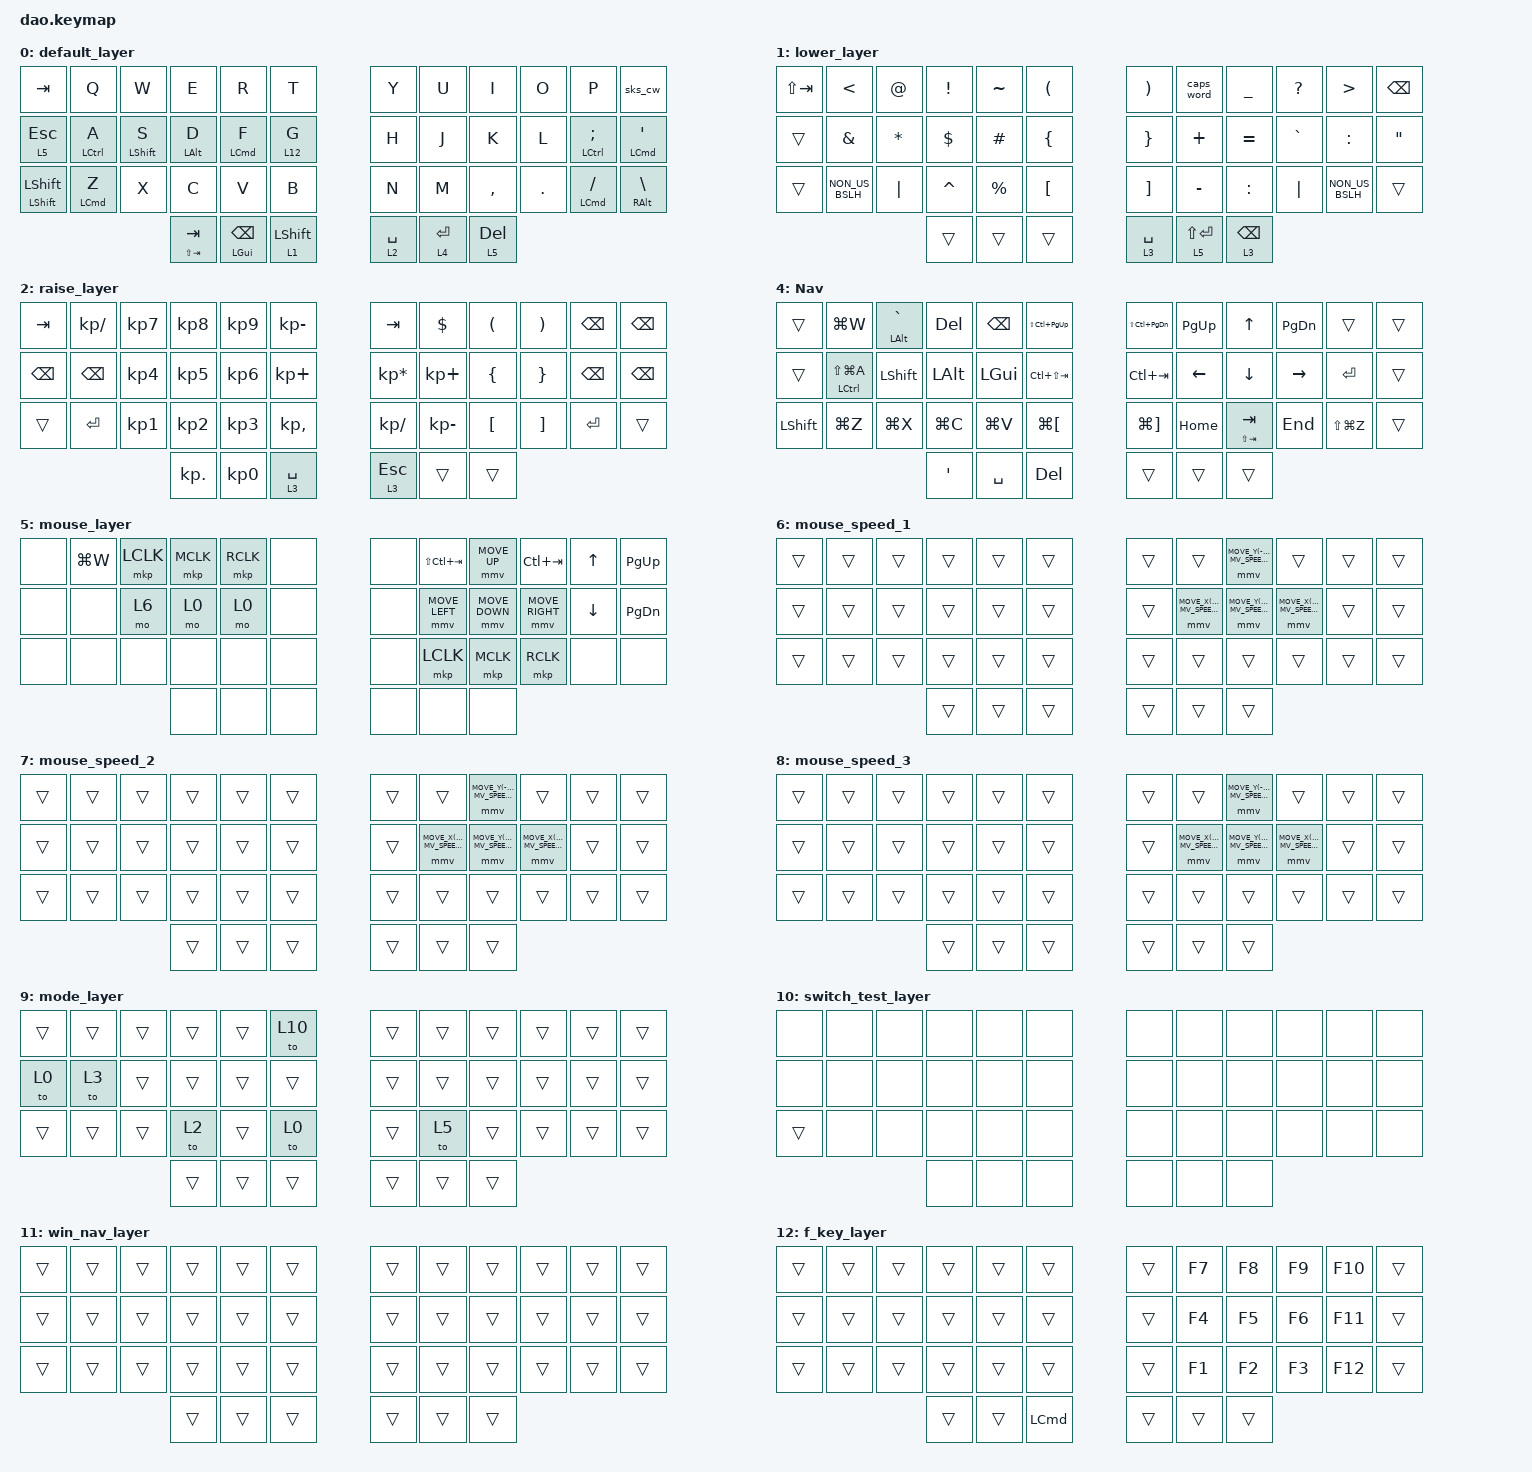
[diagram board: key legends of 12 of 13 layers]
/*
 * Copyright (c) 2021 Rafael Yumagulov
 *
 * SPDX-License-Identifier: MIT
 */

#define MOUSE_MV_SPEED_1 200
#define MOUSE_MV_SPEED_2 400
#define MOUSE_MV_SPEED_3 600

#include <behaviors.dtsi>
#include <dt-bindings/zmk/bt.h>
#include <dt-bindings/zmk/keys.h>
#include <dt-bindings/zmk/mouse.h>
#include <behaviors/mouse_keys.dtsi>

#define DEF 0
#define LWR 1
#define RSE 2
#define ADJ 3

&lt { quick_tap_ms = <200>; };

&mt { quick_tap_ms = <200>; };

&sk { quick-release; };

/*
* &mmv_const {
*     delay-ms = <0>;
*     time-to-max-speed-ms = <0>;
*     acceleration-exponent = <0>;
* };
*/

/ {
    chosen {
        zmk,matrix_transform = &default_transform;

        // zmk,matrix_transform = &extra_keys_transform;
    };
};

/ {
    behaviors {
        sks_cw: sks_cw {
            compatible = "zmk,behavior-tap-dance";
            label = "SKS_CW";
            #binding-cells = <0>;
            bindings = <&sk LSHIFT>, <&caps_word>;
        };

        kp_mod_tap_pref: kp_mod_tap_pref {
            compatible = "zmk,behavior-hold-tap";
            label = "KP_MOD_TAP_PREF";
            bindings = <&kp>, <&kp>;

            #binding-cells = <2>;
            tapping-term-ms = <200>;
            quick-tap-ms = <150>;
            flavor = "tap-preferred";
        };

        sks_mod: sks_mod {
            compatible = "zmk,behavior-hold-tap";
            label = "SKS_MOD";
            bindings = <&kp>, <&sk>;

            #binding-cells = <2>;
            tapping-term-ms = <200>;
            quick-tap-ms = <150>;
            flavor = "balanced";
        };

        krepeat_mod: krepeat_mod {
            compatible = "zmk,behavior-hold-tap";
            label = "KREPEAT_MOD";
            bindings = <&kp>, <&key_repeat>;

            #binding-cells = <2>;
            tapping-term-ms = <200>;
            quick-tap-ms = <150>;
            flavor = "balanced";
        };

        kp_layer_hold_pref: kp_layer_hold_pref {
            compatible = "zmk,behavior-hold-tap";
            label = "KP_LAYER_HOLD_PREF";
            bindings = <&mo>, <&kp>;

            #binding-cells = <2>;
            tapping-term-ms = <200>;
            quick-tap-ms = <150>;
        };

        kp_layer_tap_pref: kp_layer_tap_pref {
            compatible = "zmk,behavior-hold-tap";
            label = "KP_LAYER_TAP_PREF";
            bindings = <&mo>, <&kp>;

            #binding-cells = <2>;
            tapping-term-ms = <200>;
            quick-tap-ms = <150>;
            flavor = "tap-preferred";
        };

        kp_mod_hold_pref: kp_mod_hold_pref {
            compatible = "zmk,behavior-hold-tap";
            label = "KP_MOD_HOLD_PREF";
            bindings = <&kp>, <&kp>;

            #binding-cells = <2>;
            tapping-term-ms = <200>;
            quick-tap-ms = <150>;
            flavor = "hold-preferred";
        };

        sks_layer: sks_layer {
            compatible = "zmk,behavior-hold-tap";
            label = "SKS_LAYER";
            bindings = <&mo>, <&sk>;

            #binding-cells = <2>;
            tapping-term-ms = <200>;
            quick-tap-ms = <150>;
            flavor = "balanced";
        };

        kp_layer_balanced: kp_layer_balanced {
            compatible = "zmk,behavior-hold-tap";
            label = "KP_LAYER_BALANCED";
            bindings = <&mo>, <&kp>;

            #binding-cells = <2>;
            tapping-term-ms = <200>;
            quick-tap-ms = <150>;
            flavor = "balanced";
        };

        sks_layer_hold_pref: sks_layer_hold_pref {
            compatible = "zmk,behavior-hold-tap";
            label = "SKS_LAYER_HOLD_PREF";
            bindings = <&mo>, <&sk>;

            #binding-cells = <2>;
            tapping-term-ms = <200>;
            quick-tap-ms = <150>;
            flavor = "hold-preferred";
        };
    };

    combos {
        compatible = "zmk,combos";

        caps_word {
            bindings = <&caps_word>;
            key-positions = <37 40>;
        };

        mode_layer {
            bindings = <&tog 9>;
            key-positions = <0 38>;
        };
    };

    keymap {
        compatible = "zmk,keymap";

        default_layer {
            bindings = <
&kp TAB                 &kp Q                     &kp W                          &kp E                        &kp R                             &kp T                          &kp Y                        &kp U                         &kp I      &kp O    &kp P                             &sks_cw
&lt 5 ESC               &kp_mod_tap_pref LCTRL A  &kp_mod_tap_pref LEFT_SHIFT S  &kp_mod_tap_pref LEFT_ALT D  &kp_mod_tap_pref LCMD F           &lt 12 G                       &kp H                        &kp J                         &kp K      &kp L    &kp_mod_tap_pref LCTRL SEMICOLON  &kp_mod_tap_pref LCMD SINGLE_QUOTE
&sks_mod LSHIFT LSHIFT  &kp_mod_tap_pref LCMD Z   &kp X                          &kp C                        &kp V                             &kp B                          &kp N                        &kp M                         &kp COMMA  &kp DOT  &kp_mod_tap_pref LCMD SLASH       &mt RALT BSLH
                                                                                 &mt LS(TAB) TAB              &kp_mod_hold_pref LGUI BACKSPACE  &sks_layer_hold_pref 1 LSHIFT  &kp_layer_hold_pref 2 SPACE  &kp_layer_hold_pref 4 RETURN  &lt 5 DEL
            >;
        };

        lower_layer {
            bindings = <
&kp LS(TAB)  &kp LESS_THAN    &kp AT_SIGN  &kp EXCL    &kp TILDE    &kp LEFT_PARENTHESIS  &kp RIGHT_PARENTHESIS  &caps_word                        &kp UNDERSCORE   &kp QUESTION  &kp GREATER_THAN  &kp BACKSPACE
&trans       &kp AMPERSAND    &kp STAR     &kp DOLLAR  &kp HASH     &kp LEFT_BRACE        &kp RIGHT_BRACE        &kp PLUS                          &kp EQUAL        &kp GRAVE     &kp COLON         &kp DOUBLE_QUOTES
&trans       &kp NON_US_BSLH  &kp PIPE     &kp CARET   &kp PERCENT  &kp LEFT_BRACKET      &kp RIGHT_BRACKET      &kp MINUS                         &kp COLON        &kp PIPE      &kp NON_US_BSLH   &trans
                                           &trans      &trans       &trans                &lt 3 SPACE            &kp_layer_hold_pref 5 LS(RETURN)  &lt 3 BACKSPACE
            >;
        };

        raise_layer {
            bindings = <
&kp TAB        &kp KP_SLASH   &kp KP_N7  &kp KP_N8   &kp KP_N9  &kp KP_MINUS  &kp TAB          &kp DOLLAR    &kp LEFT_PARENTHESIS  &kp RIGHT_PARENTHESIS  &kp BACKSPACE  &kp BACKSPACE
&kp BACKSPACE  &kp BACKSPACE  &kp KP_N4  &kp KP_N5   &kp KP_N6  &kp KP_PLUS   &kp KP_MULTIPLY  &kp KP_PLUS   &kp LEFT_BRACE        &kp RIGHT_BRACE        &kp BACKSPACE  &kp BACKSPACE
&trans         &kp ENTER      &kp KP_N1  &kp KP_N2   &kp KP_N3  &kp KP_COMMA  &kp KP_DIVIDE    &kp KP_MINUS  &kp LEFT_BRACKET      &kp RIGHT_BRACKET      &kp RETURN     &trans
                                         &kp KP_DOT  &kp KP_N0  &lt 3 SPACE   &lt 3 ESC        &trans        &trans
            >;
        };

        adjust_layer {
            bindings = <
&bootloader  &kp K_PREV             &kp K_PLAY_PAUSE       &kp K_NEXT             &sys_reset             &kp LS(LA(LC(LG(T))))  &bt BT_SEL 0          &bt BT_SEL 1           &bt BT_SEL 2           &bt BT_SEL 3           &bt BT_SEL 4  &bt BT_CLR
&none        &kp LS(LA(LC(LG(A))))  &kp LS(LC(LA(LG(S))))  &kp LS(LA(LC(LG(D))))  &kp LS(LA(LC(LG(F))))  &kp C_BRIGHTNESS_DEC   &kp C_BRIGHTNESS_INC  &kp LS(LA(LC(LG(J))))  &kp LS(LA(LC(LG(K))))  &kp LS(LA(LC(LG(L))))  &none         &none
&trans       &none                  &none                  &none                  &none                  &kp C_VOL_DN           &kp C_VOL_UP          &kp K_MUTE             &none                  &none                  &none         &none
                                                           &trans                 &none                  &trans                 &trans                &none                  &trans
            >;
        };

        nav_layer {
            bindings = <
&trans     &kp LG(W)                         &mt LEFT_ALT GRAVE  &kp DELETE        &kp BACKSPACE  &kp LS(LC(PAGE_UP))  &kp LS(LC(PAGE_DOWN))  &kp PG_UP  &kp UP           &kp PG_DN  &trans         &trans
&trans     &kp_mod_tap_pref LCTRL LS(LG(A))  &kp LSHFT           &kp LALT          &kp LGUI       &kp LC(LS(TAB))      &kp LC(TAB)            &kp LEFT   &kp DOWN         &kp RIGHT  &kp RET        &trans
&kp LSHFT  &kp LG(Z)                         &kp LG(X)           &kp LG(C)         &kp LG(V)      &kp LG(LBKT)         &kp LG(RBKT)           &kp HOME   &mt LS(TAB) TAB  &kp END    &kp LS(LG(Z))  &trans
                                                                 &kp SINGLE_QUOTE  &kp SPACE      &kp DEL              &trans                 &trans     &trans
            >;

            label = "Nav";
        };

        mouse_layer {
            bindings = <
&none  &kp LG(W)  &mkp LCLK  &mkp MCLK  &mkp RCLK  &none  &none  &kp LS(LC(TAB))  &mmv MOVE_UP    &kp LC(TAB)      &kp UP_ARROW    &kp PAGE_UP
&none  &none      &mo 6      &mo 0      &mo 0      &none  &none  &mmv MOVE_LEFT   &mmv MOVE_DOWN  &mmv MOVE_RIGHT  &kp DOWN_ARROW  &kp PAGE_DOWN
&none  &none      &none      &none      &none      &none  &none  &mkp LCLK        &mkp MCLK       &mkp RCLK        &none           &none
                             &none      &none      &none  &none  &none            &none
            >;
        };

        mouse_speed_1 {
            bindings = <
&trans  &trans  &trans  &trans  &trans  &trans  &trans  &trans                 &mmv MOVE_Y(-MOUSE_MV_SPEED_1)  &trans                &trans  &trans
&trans  &trans  &trans  &trans  &trans  &trans  &trans  &mmv MOVE_X(MOUSE_MV_SPEED_1)  &mmv MOVE_Y(MOUSE_MV_SPEED_1)   &mmv MOVE_X(MOUSE_MV_SPEED_1)  &trans  &trans
&trans  &trans  &trans  &trans  &trans  &trans  &trans  &trans                 &trans                 &trans                &trans  &trans
                        &trans  &trans  &trans  &trans  &trans                 &trans
            >;
        };

        mouse_speed_2 {
            bindings = <
&trans  &trans  &trans  &trans  &trans  &trans  &trans  &trans                 &mmv MOVE_Y(-MOUSE_MV_SPEED_2)  &trans                &trans  &trans
&trans  &trans  &trans  &trans  &trans  &trans  &trans  &mmv MOVE_X(MOUSE_MV_SPEED_2)  &mmv MOVE_Y(MOUSE_MV_SPEED_2)   &mmv MOVE_X(MOUSE_MV_SPEED_2)  &trans  &trans
&trans  &trans  &trans  &trans  &trans  &trans  &trans  &trans                 &trans                 &trans                &trans  &trans
                        &trans  &trans  &trans  &trans  &trans                 &trans
            >;
        };

        mouse_speed_3 {
            bindings = <
&trans  &trans  &trans  &trans  &trans  &trans  &trans  &trans                 &mmv MOVE_Y(-MOUSE_MV_SPEED_3)  &trans                &trans  &trans
&trans  &trans  &trans  &trans  &trans  &trans  &trans  &mmv MOVE_X(MOUSE_MV_SPEED_3)  &mmv MOVE_Y(MOUSE_MV_SPEED_3)   &mmv MOVE_X(MOUSE_MV_SPEED_3)  &trans  &trans
&trans  &trans  &trans  &trans  &trans  &trans  &trans  &trans                 &trans                 &trans                &trans  &trans
                        &trans  &trans  &trans  &trans  &trans                 &trans
            >;
        };

        mode_layer {
            bindings = <
&trans  &trans  &trans  &trans  &trans  &to 10  &trans  &trans  &trans  &trans  &trans  &trans
&to 0   &to 3   &trans  &trans  &trans  &trans  &trans  &trans  &trans  &trans  &trans  &trans
&trans  &trans  &trans  &to 2   &trans  &to 0   &trans  &to 5   &trans  &trans  &trans  &trans
                        &trans  &trans  &trans  &trans  &trans  &trans
            >;
        };

        switch_test_layer {
            bindings = <
&none   &none  &none  &none  &none  &none  &none  &none  &none  &none  &none  &none
&none   &none  &none  &none  &none  &none  &none  &none  &none  &none  &none  &none
&trans  &none  &none  &none  &none  &none  &none  &none  &none  &none  &none  &none
                      &none  &none  &none  &none  &none  &none
            >;
        };

        win_nav_layer {
            bindings = <
&trans  &trans  &trans  &trans  &trans  &trans  &trans  &trans  &trans  &trans  &trans  &trans
&trans  &trans  &trans  &trans  &trans  &trans  &trans  &trans  &trans  &trans  &trans  &trans
&trans  &trans  &trans  &trans  &trans  &trans  &trans  &trans  &trans  &trans  &trans  &trans
                        &trans  &trans  &trans  &trans  &trans  &trans
            >;
        };

        f_key_layer {
            bindings = <
&trans  &trans  &trans  &trans  &trans  &trans    &trans  &kp F7  &kp F8  &kp F9  &kp F10  &trans
&trans  &trans  &trans  &trans  &trans  &trans    &trans  &kp F4  &kp F5  &kp F6  &kp F11  &trans
&trans  &trans  &trans  &trans  &trans  &trans    &trans  &kp F1  &kp F2  &kp F3  &kp F12  &trans
                        &trans  &trans  &kp LCMD  &trans  &trans  &trans
            >;
        };
    };
};
